# dm646x_cslr_sys_001 register map
Vendor: Texas Instruments
Peripheral module from a debugger description file.
Registers are 32-bit, access not given, reset 0x0 unless marked. A register's access mark holds for its fields unless they carry their own. Offsets are as the file gives them; lines under a group give offsets from that group; [hi:lo] are bit positions; {n}, {i} and the like mark numbered series; 'fields as' and 'values as' point back to an identical list; <NAME> marks a mode.

## SYS — System Module (ch5_Chip_Configuration_0p19.pdf)
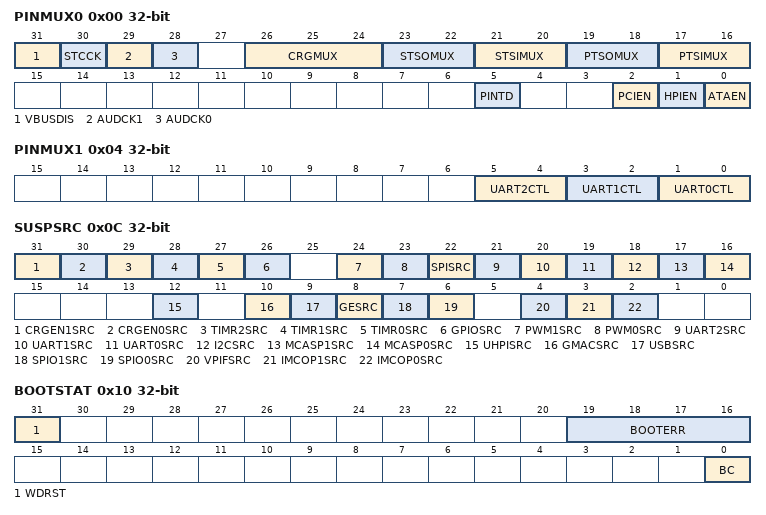
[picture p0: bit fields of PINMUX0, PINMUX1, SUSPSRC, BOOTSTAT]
0x00 PINMUX0
  [31] VBUSDIS rw — Disable USB_DRVVBUS output 0 = USB_DRVVBUS function selected 1 = GP22 function selected
    0=USB_DRVVBUS; 1=GP22
  [30] STCCK rw — Enable STC source clock input 0 = GP04_INT04 function selected 1 = STCSRC_CLKIN function selected
    0=GP04_INT04; 1=STCSRC_CLKIN
  [29] AUDCK1 rw — Enable AUDIO_CLK1 output 0 = GP02_INT02 function selected 1 = AUDIO_CLK1 function selected
    0=GP02_INT02; 1=ENABLE
  [28] AUDCK0 rw — Enable AUDIO_CLK0 output 0 = GP03_INT03 function selected 1 = AUDIO_CLK0 function selected
    0=GP03_INT03; 1=ENABLE
  [26:24] CRGMUX rw — CRGEN pin mux control (See Section 5.2.9) 000 = No CRGEN signals enabled 001 = CRGEN1 selection enabled (mux'd with UART2 data) 010 = Reserved (no CRGEN signals enabled) 011 = Reserved (no CRGEN signals enabled) 100 = CRGEN0 selection enabled (mux'd with UART2_CTS & PWM0) 101 = CRGEN0 & CRGEN1 selection enabled 110 = CRGEN0 selection enabled (mux'd with UART2 data) 111 = Reserved (no CRGEN signals enabled)
    0=NOCRGEN; 1=CRGEN1_MUXWITH_UART2DATA; 4=CRGEN0_MUXWITH_PWM0; 5=CRGEN0_CRGEN1; 6=CRGEN0_MUXWITH_UART2DATA
  [23:22] STSOMUX rw — STSO pin mux control (See Section 5.2.8) 0x = No STSO signals enabled 10 = STSO selection enabled (mux'd on VPIF_DOUT pins) 11 = STSO selection enabled (mux'd on UART0_RIN, UART2_CTSn, PWM0, and PWM1 pins)
    0=NOSTSO; 2=ENABLE_MUXWITH_VPIF_DOUT; 3=ENABLE_MUXWITH_UART_PWM
  [21:20] STSIMUX rw — STSI pin mux control (See Section 5.2.7) 00 = No STSI signals enabled 01 = STSI selection enabled (mux'd on UART0 pins) 10 = STSI selection enabled (mux'd on VPIF_DOUT pins) 11 = STSI selection enabled (mux'd on VPIF_DIN pins)
    0=NOSTSI; 1=ENABLE_MUXWITH_UART0; 2=ENABLE_MUXWITH_VPIF_DOUT; 3=ENABLE_MUXWITH_VPIF_DIN
  [19:18] PTSOMUX rw — PTSO pin mux control 00 = No PTSO signals enabled 01 = No PTSO signals enabled 10 = PTSO parallel muxing enabled (mux w/ VPIF_DIN) 11 = PTSO serial muxing enabled (mux D w/ UART1)
    0=NOPTSO; 1=NOPTSO1; 2=ENABLE_MUX_VPIF_DIN; 3=ENABLE_MUX_UART1
  [17:16] PTSIMUX rw — PTSO pin mux control 00 = No PTSI signals enabled 01 = No PTSI signals enabled 10 = PTSI parallel muxing enabled (mux w/ VPIF_DIN) 11 = PTSI serial muxing enabled (mux D w/ UART1)
    0=NOPTSI; 1=NOPTSI1; 2=ENABLE_MUX_VPIF_DIN; 3=ENABLE_MUX_UART1
  [5] PINTD rw — PCI INTD Function 0 = Pin functions as GP05_INT05 1 = Pin functions as PCI INTD input
    0=GP05_INT05_FUN; 1=PCI_INTD_FUN
  [2] PCIEN rw — PCI Function Enable
  [1] HPIEN rw — UHPI Function Enable
  [0] ATAEN rw — ATA Function Enable
0x04 PINMUX1
  [5:4] UART2CTL rw — UART2 pin configuration 00 = UART function with flow control 01 = UART function without flow control 10 = IrDA/CIR function 11 = GPIO function (Individual pin functions may be overridden by PTSIMUX, CRGEN0 and CRGEN1 values)
    0=UART_WITH_FLOW; 1=UART_WITHOUT_FLOW; 2=IRDA_CIR; 3=GPIO
  [3:2] UART1CTL rw — UART1 pin configuration 00 = UART function with flow control 01 = UART function without flow control 10 = IrDA/CIR function 11 = GPIO function (Individual pin functions may be overridden by PTSIMUX and PTSOMUX values)
    0=UART_WITH_FLOW; 1=UART_WITHOUT_FLOW; 2=IRDA_CIR; 3=GPIO
  [1:0] UART0CTL rw — UART0 pin configuration (See Section 5.2.10) 00 = UART function with modem control 01 = UART function without modem control 1x = IrDA/CIR function (Individual pin functions may be overridden by PTSOMUX, value)
    0=UART_WITH_MODEM; 1=UART_WITHOUT_MODEM; 2=IRDA_CIR
0x08 DSPBOOTADDR rw reset 0x42200000 — DSP Boot Address
  [31:0] BOOTADDR — \hDSP Boot Address . Upper 22 bits of DSP reset vector are stored in upper 22 bits of the register and the 10 LSBs are ignored . Note that this must point to an address range from which GEM can perform instruction fetches. Thus is limited to the following address ranges: L1P : 0x00E0:0000  0x00E0:7FFF. AEMIF: 0x42xx:xxxx  0x49FF:FFFF. DDR : 0x8000:0000  0x8FFF:FFFF
0x0C SUSPSRC — Determines which processor emulator (ARM or GEM) controls peripheral emulation suspend
  [31] CRGEN1SRC rw — Clock Recovery Generator 1 emulation
    0=ARMEMU (Receives EMU suspend on ARM suspend); 1=GEMEMU (Receives EMU suspend on GEM suspend)
  [30] CRGEN0SRC rw — Clock Recovery Generator 0 emulation
    0=ARMEMU; 1=GEMEMU
  [29] TIMR2SRC rw — EMU suspend source for TIMER2 (WDTIMER)
    values as CRGEN1SRC
  [28] TIMR1SRC rw — EMU suspend source for TIMER1
    values as CRGEN1SRC
  [27] TIMR0SRC rw — EMU suspend source for TIMER0
    values as CRGEN1SRC
  [26] GPIOSRC rw — EMU suspend source for GPIO
    values as CRGEN1SRC
  [24] PWM1SRC rw — EMU suspend source for PWM1
    values as CRGEN1SRC
  [23] PWM0SRC rw — EMU suspend source for PWM0
    values as CRGEN1SRC
  [22] SPISRC rw — EMU suspend source for SPI
    values as CRGEN1SRC
  [21] UART2SRC rw — EMU suspend source for UART2
    values as CRGEN1SRC
  [20] UART1SRC rw — EMU suspend source for UART1
    values as CRGEN1SRC
  [19] UART0SRC rw — EMU suspend source for UART0
    values as CRGEN1SRC
  [18] I2CSRC rw — EMU suspend source for I2C
    values as CRGEN1SRC
  [17] MCASP1SRC rw — EMU suspend source for MCASP1
    values as CRGEN1SRC
  [16] MCASP0SRC rw — EMU suspend source for MCASP0
    values as CRGEN1SRC
  [12] UHPISRC rw — EMU suspend source for UHPI
    values as CRGEN1SRC
  [10] GMACSRC rw — Ethernet MAC emulation suspend source
    values as CRGEN1SRC
  [9] USBSRC rw — EMU suspend source for USB
    values as CRGEN1SRC
  [8] GESRC rw — Graphic Engine emulation suspend source
    values as CRGEN1SRC
  [7] SPIO1SRC rw — Stream I/O 1 emulation suspend source
    values as CRGEN1SRC
  [6] SPIO0SRC rw — Stream I/O 0 emulation suspend source
    values as CRGEN1SRC
  [4] VPIFSRC rw — Video Port emulation suspend source
    values as CRGEN1SRC
  [3] IMCOP1SRC rw — HD-ImCOP1 emulation suspend source
    values as CRGEN1SRC
  [2] IMCOP0SRC rw — HD-ImCOP0 emulation suspend source
    values as CRGEN1SRC
0x10 BOOTSTAT — Boot Status
  [31] WDRST rw — Watchdog Timer Reset 0 = Device reset was not a result of timeout. 1 = Device was reset be a watchdog timer timeout. This is a "sticky" bit that can be used to debug WD timeout conditions. The bit is set when a WD timeout occurs (TOUT4). This bit is reset (to 0) by a PORn reset only. It is NOT cleared by a Warm Reset or soft reset. The bit may be cleared by writing a '1'.
    0=NOTIMEOUT; 1=TIMEOUT
  [19:16] BOOTERR rw — Boot Error 0000 = No Boot Error Others = Bootloader detected boot error The exact meaning of the various error codes will be determined by the bootloader software.
    0=NOERROR
  [0] BC rw — Boot Complete 0 = Host has not complete its boot sequence 1 = Host boot sequence is complete This bit may be optionally set by a host boot device (such as PCI or UHPI) to indicate that it has finished loading code. The ARM926 can poll this bit to determine whether to continue the boot process.
    0=BOOT_NOTCOMPLETE; 1=BOOT_COMPLETE
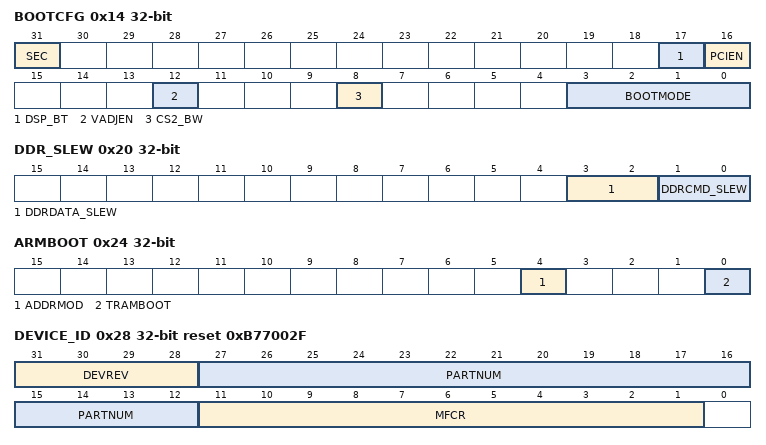
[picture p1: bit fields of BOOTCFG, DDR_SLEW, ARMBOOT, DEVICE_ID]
0x14 BOOTCFG
  [31] SEC ro — Secure Device 0 = Non-secure device 1 = Secure device This bit is not latched at the end of global hard reset.
    0=NON_SECURE_DEV; 1=SECURE_DEV
  [17] DSP_BT ro — DSP Boot 0 = ARM boots GEM 1 = GEM self-boots This bit has no meaning on GEM-only devices. For ARM/GEM devices, will cause the GEM to be released from reset automatically. GEM will boot from secure ROM on secure devices or from AEMIF on nonsecure devices. If BOOTMODE = 0001 or 0010, or PCIEN=1 on non-secure devices, then GEM self-boot will fail since the AEMIF will be disabled.
    0=ARM_BOOT; 1=GEM_SELF_BOOT
  [16] PCIEN ro — PCI Enable 0 = PCI Disabled 1 = PCI Enabled Disables internal pullup and pulldown resistors on PCI pins and configures pin muxing for PCI.
    0=DISABLE; 1=ENABLE
  [12] VADJEN ro — Voltage Adjust Enable 0 = SmartReflex outputs disabled 1 = SmartReflex outputs enabled Determines whether GP_INT[07:06] will function as GPIOs or SmartReflex control outputs.
    0=DISABLE; 1=ENABLE
  [8] CS2_BW ro — AEMIF CS2 Default Bus Width 0 = Default to 8-bit operation 1 = Default to 16-bit operation Determines the default bus width of the AEMIF CS2 memory space. This ensures that boot from AEMIF (ARM or GEM) will correctly read the attached memory.
    0=8BIT; 1=16BIT
  [3:0] BOOTMODE ro — Boot Mode 0000 = EMU Boot 0001 = Reserved 0010 = UHPI-16 (if PCIEN = 0) PCI w/o auto-init (if PCIEN = 1) 0011 = UHPI-32 (if PCIEN = 0) PCI w/ auto-init (if PCIEN = 1) 0100 = AEMIF direct (if SEC = 0), AEMIF through ROM (if SEC = 1) Error (if PCIEN = 1)  default to UART0 0101 = Reserved 0110 = I2C Boot 0111 = NAND Flash (if PCIEN = 0) Error (if PCIEN = 1) 1000 = UART0 Boot 1001 = Emulation Boot 1010 = VLYNQ Boot 1011 = EMAC Boot 1110 = SPI Boot Others = Reserved
0x18 SMTREFLEX — Smart Reflex control status Register
  [1:0] SMTREFLEX ro — eFuse programmed adjustment values for 1.2V core operation. Reflects the value output on the SMTREFLEX[1:0] pins.
0x20 DDR_SLEW — DDR Slew Rate
  [3:2] DDRDATA_SLEW ro — DDR data
  [1:0] DDRCMD_SLEW ro — DDR command
0x24 ARMBOOT — ARM926 Boot Control
  [4] ADDRMOD rw — IAHB Address Modification 0 = No address modification 1 = Address bit 30 is tied high to modify IAHB fetch address to point to AEMIF
    0=DISABLE_MODIFY; 1=ENABLE_MODIFY
  [0] TRAMBOOT rw — ARM TCM RAM Boot 0 = Use BTMODE selected bootmode 1 = Boot from ITCM RAM
    0=USE_BTMODE; 1=RAM_BOOT
0x28 DEVICE_ID reset 0xB77002F — Device Identification
  [31:28] DEVREV ro — Device revision
  [27:12] PARTNUM ro — Device part number (unique JTAG ID)
  [11:1] MFCR ro — Manufacturer's JTAG ID
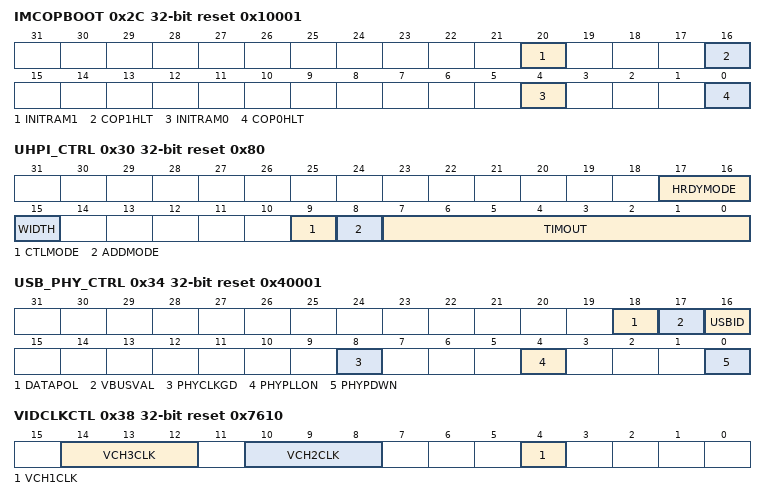
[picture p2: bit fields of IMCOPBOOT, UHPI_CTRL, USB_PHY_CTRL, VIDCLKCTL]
0x2C IMCOPBOOT reset 0x10001 — ImCOP Boot Control register
  [20] INITRAM1 rw — ImCOP1 INITRAM Input 0 = Internal TCM disabled 1 = Internal TCM enabled This bit determines if ARM fetches its first instruction from TCM memory or external memory. The default value is 0 at reset. After TCM RAM is loaded, software may set the value to 1 to enable subsequent resets from TCM
    0=TCM_DISABLE; 1=TCM_ENABLE
  [16] COP1HLT rw — ImCOP1 Fetch Halt 0 = IAHB fetch enabled 1 = IAHB fetch stalled This bit determines the value on the WAIT input of the ARM968 AHB bus. By pulling WAIT high, the instruction fetch is stalled. This allows the TCM RAM to be loaded by another device or EDMA. Afterwards, the ImCOP can be reset again with INITRAM enabled and COP1HLT disabled to execute from TCM
    0=IAHB_FETCH_ENABLE; 1=IAHB_FETCH_STALLED
  [4] INITRAM0 rw — ImCOP0 INITRAM Input 0 = Internal TCM disabled 1 = Internal TCM enabled This bit determines if ARM fetches its first instruction from TCM memory or external memory. The default value is 0 at reset. After TCM RAM is loaded, software may set the value to 1 to enable subsequent resets from TCM
    0=TCM_DISABLE; 1=TCM_ENABLE
  [0] COP0HLT rw — ImCOP0 Fetch Halt 0 = IAHB fetch enabled 1 = IAHB fetch stalled This bit determines the value on the WAIT input of the ARM968 AHB bus. By pulling WAIT high, the instruction fetch is stalled. This allows the TCM RAM to be loaded by another device or EDMA. Afterwards, the ImCOP can be reset again with INITRAM enabled and COP1HLT disabled to execute from TCM
    0=IAHB_FETCH_ENABLE; 1=IAHB_FETCH_STALLED
0x30 UHPI_CTRL reset 0x80 — UHPI Control
  [17:16] HRDYMODE rw — HRDY output mode 00 = HRDYn (active low) signal is output 01 = HRDY (active high) signal is output 10 = InternalHRDYn signal is output 11 = InternalHRDY signal is output
    0=HRDYN_ACTIVE_LOW; 1=HRDY_ACTIVE_HIGH; 2=INTERNAL_HRDYN; 3=INTERNAL_HRDY
  [15] WIDTH rw — UHPI Data Width 0 = Half width (16-bit) data bus 1 = Full width (32-bit) data bus This bit value must be determined before releasing the UHPI from reset to ensure correct UHPI operation.
    0=16BIT; 1=32BIT
  [9] CTLMODE rw — HPIC register write access 0 = Host 1 = DaVinci-HD (if ADDMODE = 1)
    0=HOST; 1=DAVINCIHD
  [8] ADDMODE rw — HPIA register write access 0 = Host 1 = DaVinci-HD
    0=HOST; 1=DAVINCIHD
  [7:0] TIMOUT rw — Host burst write timeout value
0x34 USB_PHY_CTRL reset 0x40001 — USB PHY Control
  [18] DATAPOL rw — Determines UDB data polarity 0 = Inverted data 1 = Normal data polarity
    0=INVERTED; 1=NORMAL
  [17] VBUSVAL rw — VBUS sense control 0 = Disabled 1 = Session start
    0=DISABLE; 1=SESSION_START
  [16] USBID rw — USB Mode 0 = Host 1 = Peripheral
    0=HOST; 1=PERIPHERAL
  [8] PHYCLKGD ro — USB PHY Power and Clock Good 0 = Phy power not ramped or PLL not locked 1 = Phy power is good and PLL is locked
    0=NOT_GOOD; 1=GOOD
  [4] PHYPLLON rw — USB PHY PLL suspend override 0 = Normal PLL operation 1 = Override PLL suspend state
    0=NORMAL_OPER; 1=OVERRIDE_SUSP_STATE
  [0] PHYPDWN rw — USB PHY power down control 0 = PHY powered 1 = PHY power off
    0=PWRED; 1=PWROFF
0x38 VIDCLKCTL reset 0x7610 — Video Clock Control
  [14:12] VCH3CLK rw — Video Channel 3 Clock Source Selects the clock source for the Ch3 output source clock. 000 : CRG0_VCXI (external pin) 001 : CRG1_VCXI (external pin) 010 : Sysclk8 (PLLCTRL0) 011 : Auxclk (PLLCTRL0) 100 : VPIF_CLKIN0 (external pin) 101 : V27_PLLIN (external pin) 110 : VPIF_CLKIN2 (external pin) 111 : VPIF_CLKIN3 (external pin)
    0=CRG0_VCXI; 1=CRG1_VCXI; 2=Sysclk8; 3=Auxclk; 4=VPIF_CLKIN0; 5=V27_PLLIN; 6=VPIF_CLKIN2; 7=VPIF_CLKIN3
  [10:8] VCH2CLK rw — Video Channel 2 Clock Source Selects the clock source for the Ch2 output source clock. 000 : CRG0_VCXI (external pin) 001 : CRG1_VCXI (external pin) 010 : Sysclk8 (PLLCTRL0) 011 : Auxclk (PLLCTRL0) 100 : VPIF_CLKIN0 (external pin) 101 : V27_PLLIN (external pin) 110 : VPIF_CLKIN2 (external pin) 111 : Reserved
    0=CRG0_VCXI; 1=CRG1_VCXI; 2=Sysclk8; 3=Auxclk; 4=VPIF_CLKIN0; 5=V27_PLLIN; 6=VPIF_CLKIN2
  [4] VCH1CLK rw — Video Channel 1 Clock Source Selects the clock source for the Ch1 input clock. 0 : VPIF_CLKIN0 (external pin) 1 : VPIF_CLKIN1 (external pin)
    0=VPIF_CLKIN0; 1=VPIF_CLKIN1
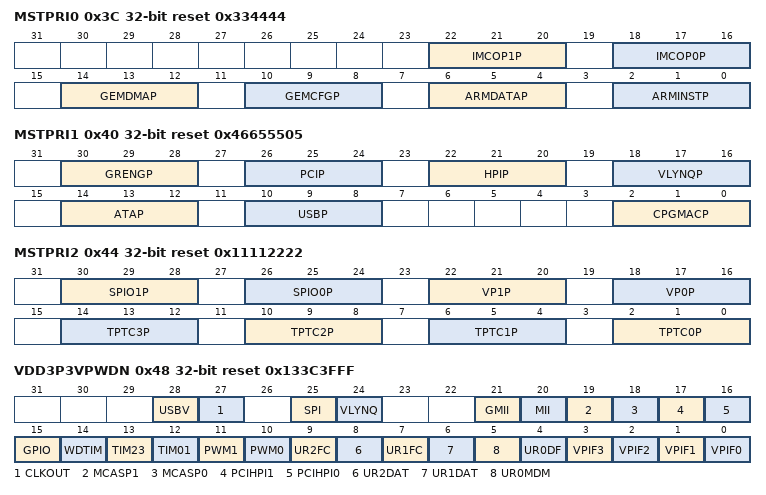
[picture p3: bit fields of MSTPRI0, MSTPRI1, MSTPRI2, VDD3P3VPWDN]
0x3C MSTPRI0 reset 0x334444 — Master Priorities Reg0
  [22:20] IMCOP1P rw — ImCOP1 bus priority
  [18:16] IMCOP0P rw — ImCOP0 bus priority
  [14:12] GEMDMAP rw — GEM DMA bus priority
  [10:8] GEMCFGP rw — GEM CFG bus priority
  [6:4] ARMDATAP rw — ARM DATA bus priority
  [2:0] ARMINSTP rw — ARM INSTRUCTION bus priority
0x40 MSTPRI1 reset 0x46655505 — Master Priorities Reg1
  [30:28] GRENGP rw — UHPI bus priority
  [26:24] PCIP rw — PCI bus priority
  [22:20] HPIP rw — HPI bus priority
  [18:16] VLYNQP rw — VLYNQ bus priority
  [14:12] ATAP rw — ATA bus priority
  [10:8] USBP rw — USB bus priority
  [2:0] CPGMACP rw — EMAC bus priority
0x44 MSTPRI2 reset 0x11112222 — Master Priorities Reg2
  [30:28] SPIO1P rw — SPIO1 bus priority
  [26:24] SPIO0P rw — SPIO0 bus priority
  [22:20] VP1P rw — Video Port1 bus priority
  [18:16] VP0P rw — Video Port0 bus priority
  [4n+2:4n] TPTC{n}P rw (n=0..3) — TPTC {n} bus priority
0x48 VDD3P3VPWDN reset 0x133C3FFF — VDD 3.3V I/O powerdown control
  [all] fields
    0=PWUP; 1=PWDOWN
  [28] USBV rw — USB_DRVBUS Powerdown Control: 0 = i/o cells powered up 1 = i/o cells powered down Controls USB_DRVVBUS pin.
  [27] CLKOUT rw — CLKOUT Powerdown Control: 0 = i/o cells powered up 1 = i/o cells powered down Controls CLKOUT pin. Defaults to powered to facilitate debug.
  [25] SPI rw — SPI Powerdown Control Controls 6 SPI interface pins
  [24] VLYNQ rw — VLYNQ Powerdown Control Controls 10 VLYNQ interface pins
  [21] GMII rw — GMIII Powerdown Control Controls the 10 pins used by GMII (Gigibit) only. MII_RFTCLK, MII_GMTCLK, MII_MTXD[7:4] and MII_MRXD[7:4]
  [20] MII rw — MIII Powerdown Control Controls the 17 pins used by (G)MII (10/100/Gig) and MDIO interfaces. MII_MTCLK, MII_MTXD[3:0], MII_MTXEN, MII_MCOL, MII_MCRS, MII_MRCLK, MII_MRXD[3:0], MII_MRXDV, MII_MRXER, MDIO_MDCLK, and MDIO_MDIO
  [19] MCASP1 rw — McASP1 Powerdown Control Controls the 3 McASP1 pins
  [18] MCASP0 rw — McASP0 Powerdown Control Controls the 12 McASP1 pins
  [17] PCIHPI1 rw — PCI / UHPI / AEMIF / ATA Powerdown Control Controls the 27 pins used by ATA or PCI, UHPI, or AEMIF. Defaults to powered up for NOR boot
  [16] PCIHPI0 rw — PCI / UHPI / AEMIF Powerdown Control Controls the 29 pins used by PCI, UHPI, or AEMIF but not shared with ATA. Does not include GP[7:5]_INT[7:5] Defaults to powered up for NOR boot
  [15] GPIO rw — GPIO Powerdown Control Controls the 8 GP_INT[7:0] pins. Defaults to powered up.
  [14] WDTIM rw — WD Timer Powerdown Control Controls the WD Timer pin TOUT4.
  [13] TIM23 rw — Timer1 Powerdown Control Controls the 3 Timer1 pins TIN2, TOUT2, TOUT3
  [12] TIM01 rw — Timer0 Powerdown Control Controls the 4 Timer0 pins TIN0, TOUT0. TIN1, TOUT1
  [11] PWM1 rw — PWM1 Powerdown Control Controls the PWM1 / GP36 pin
  [10] PWM0 rw — PWM0 Powerdown Control Controls the PWM0 / GP37 / CRG0_PWMO pin
  [9] UR2FC rw — UART2 Flow Control Powerdown Control Controls the UART2_RTSn / PTSI_PSTART and UART2_CTSn / CRG0_PWMO pins
  [8] UR2DAT rw — UART2 Data Powerdown Control Controls the UART2_RXD / CRG1_VCXI and UART2_TXD / CRG1_PWMO pins
  [7] UR1FC rw — UART1 Flow Control Powerdown Control Controls the UART1_RTSn / PTSI_ERR and UART1_CTSn / PTSI_VALID pins
  [6] UR1DAT rw — UART1 Data Powerdown Control Controls the UART1_RXD / PTSI_D7 and UART1_TXD / PTSO_D7 pins
  [5] UR0MDM rw — UART0 Modem Control Powerdown Control Controls UART0_DTRn / PTSO_VALID, UART0_DSRn / PTSO_PSTART, UART0_DCDn / PTSO_ERR and UART0_RIN / GP08 pins
  [4] UR0DF rw — UART0 Data and Flow Powerdown Control Controls UART0_RXD, UART0_TXD, UART0_RTSn, and UART0_CTSn pins
  [3] VPIF3 rw — VPIF MSB Output Powerdown Control Controls the VPIF_DOUT[15:8] / STSO / STSI, VPIF_CLKIN3 / STSO_CLK, and VPIF_CLKO3 / PTSO_CLK pins
  [2] VPIF2 rw — VPIF LSB Output Powerdown Control Controls the VPIF_DOUT[7:0], VPIF_CLKIN2, and VPIF_CLKO2 pins
  [1] VPIF1 rw — VPIF MSB Input Powerdown Control Controls the VPIF_DIN[15:8] / PTSI_D[7:0], and VPIF_CLKIN1 pins
  [0] VPIF0 rw — VPIF LSB Input Powerdown Control Controls the VPIF_DIN[7:0] / PTSO_D[7:0] / STSI and VPIF_CLKIN0 pins
0x4C DFTENABLE — Enable access to DFT MMRs
  [0] DFT_EN rw — Setting the DFTEN bit allows program access to the DFT MMR registers (including the die ID register).
    0=DISABLE; 1=ENABLE
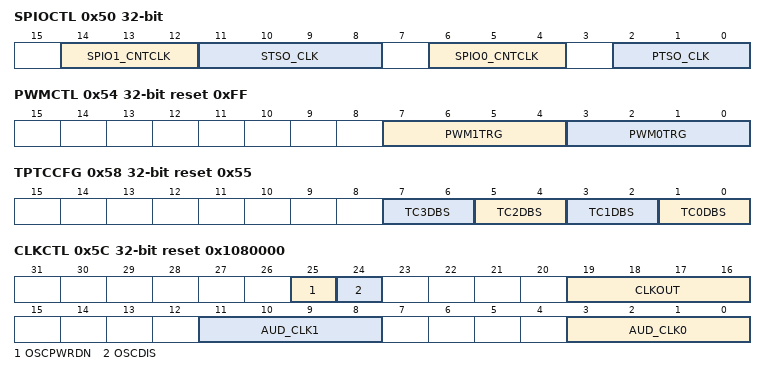
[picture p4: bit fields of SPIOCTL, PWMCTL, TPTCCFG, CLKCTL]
0x50 SPIOCTL — SPIO Control Register
  [14:12] SPIO1_CNTCLK rw — SPIO1 Counter Clock Source Selects the clock source for Stream I/O 1 module's counter (m27_clk signal) 000 : CRG1_VCXI (external pin) 001 : STCSRC_CLKIN (external pin) 010 : AUXCLK (PLLCTL0 output  27 MHz) 011 : CRG0_VCXI (external pin) 100 : VPIF_CLKIN2 (external pin) 101 : VPIF_CLKIN3 (external pin) 110 : Reserved 111 : Reserved
    0=CRG1_VCXI; 1=STCSRC_CLKIN; 2=AUXCLK; 3=CRG0_VCXI; 4=VPIF_CLKIN2; 5=VPIF_CLKIN3
  [11:8] STSO_CLK rw — SPIO1 STSO Output Clock Source Selects the clock source for Stream I/O 1 output source clock (str_tx_clk_i signal) 0000 : CRG1_VCXI (external pin) 0001 : STCSRC_CLKIN (external pin) 0010 : Sysclk6 (PLLCTL0) 0011 : Sysclkbp PLLCTL0) 0100 : VPIF_CLKIN0 (external pin) 0101 : STSI_CLK (external pin) 0110 : VPIF_CLKIN2 (external pin) 0111 : Reserved 1000 : CRG0_VCXI 1001 : Reserved 1xx1 : Reserved
    0=CRG1_VCXI; 1=STCSRC_CLKIN; 2=Sysclk6; 3=Sysclkbp; 4=VPIF_CLKIN0; 5=STSI_CLK; 6=VPIF_CLKIN2; 8=CRG0_VCXI
  [6:4] SPIO0_CNTCLK rw — SPIO0 Counter Clock Source Selects the clock source for Stream I/O 0 module's counter (m27_clk signal) 000 : CRG0_VCXI (external pin) 001 : STCSRC_CLKIN (external pin) 010 : AUXCLK (PLLCTL0 output  27 MHz) 011 : CRG1_VCXI (external pin) 100 : VPIF_CLKIN0 (external pin) 101 : VPIF_CLKIN1 (external pin) 110 : Reserved 111 : Reserved
    0=CRG0_VCXI; 1=STCSRC_CLKIN; 2=AUXCLK; 3=CRG1_VCXI; 4=VPIF_CLKIN0; 5=VPIF_CLKIN1
  [2:0] PTSO_CLK rw — SPIO0 PTSO Output Clock Source Selects the clock source for Stream I/O 0 output source clock (str_tx_clk_i signal) 000 : CRG0_VCXI (external pin) 001 : STCSRC_CLKIN (external pin) 010 : Sysclk5 (PLLCTL0) 011 : Sysclkbp PLLCTL0) 100 : VPIF_CLKIN0 (external pin) 101 : VPIF_CLKIN1 (external pin) 110 : PTSI_CLK (external pin) 111 : CRG1_VCXI (external pin)
    0=CRG0_VCXI; 1=STCSRC_CLKIN; 2=Sysclk5; 3=Sysclkbp; 4=VPIF_CLKIN0; 5=VPIF_CLKIN1; 6=PTSI_CLK; 7=CRG1_VCXI
0x54 PWMCTL reset 0xFF — PWM Control Register
  [7:4] PWM1TRG rw — PWM1 Trigger Source 0000 = GPIO0 1000 = VPIF Vert Int0 0001 = GPIO1 1001 = VPIF Vert Int1 0010 = GPIO2 1010 = VPIF Vert Int2 0011 = GPIO3 1011 = VPIF Vert Int3 0100 = GPIO4 1100 = Disabled 0101 = GPIO5 1101 = Disabled 0110 = GPIO6 1110 = Disabled 0111 = GPIO7 1111 = Disabled
  [3:0] PWM0TRG rw — PWM0 Trigger Source 0000 = GPIO0 1000 = VPIF Vert Int0 0001 = GPIO1 1001 = VPIF Vert Int1 0010 = GPIO2 1010 = VPIF Vert Int2 0011 = GPIO3 1011 = VPIF Vert Int3 0100 = GPIO4 1100 = Disabled 0101 = GPIO5 1101 = Disabled 0110 = GPIO6 1110 = Disabled 0111 = GPIO7 1111 = Disabled
0x58 TPTCCFG reset 0x55 — TPTC Configuration
  [all] fields
    0=16BYTE; 1=32BYTE; 2=64BYTE
  [2n+1:2n] TC{n}DBS rw (n=0..3) — TC{n} Default Burst Size 00 = 16 byte 01 = 32 byte 10 = 64 byte 11 = reserved
0x5C CLKCTL reset 0x1080000 — Oscillator and output control
  [25] OSCPWRDN rw — Aux Oscillator Powerdown Controls internal bias resistor connection 0 = Internal bias resistor connected (normal operation) 1 = Internal bias resistor disconnected (external bias resistor required or clock input used)
    0=BIAS_REG_CONNECTED; 1=BIAS_REG_DISCONNECTED
  [24] OSCDIS rw — Aux Oscillator Disable Disables the oscillator 0 = Oscillator enabled (normal operation) 1 = Oscillator disabled (clock input used or not Aux clock required)
    0=AUX_OSC_ENABLE; 1=AUX_OSC_DISABLE
  [19:16] CLKOUT rw — CLKOUT Source Selects the clock source for the CLKOUT output 0000 : Disabled 1000 : Sysclk8 0001 : Auxclk 1001 : Sysclk9 0010 : Obsclk 1010 : X1_AUX 0011 : Sysclk3 1011 : Reserved 0100 : Sysclk4 1100 : Reserved 0101 : Sysclk5 1101 : Reserved 0110 : Sysclk6 1110 : Reserved 0111 : Sysclk7 1111 : Reserved
  [11:8] AUD_CLK1 rw — AUDIO_CLK1 Source Selects the clock source for the AUDIO_CLK1 output 0000 : Disabled 1000 : X1_AUX 0001 : Auxclk 1001 : V27_PLLIN 0010 : CRG0_VCXI 1010 : Reserved 0011 : CRG1_VCXI 1011 : Reserved 0100 : VPIF_CLKIN0 1100 : Reserved 0101 : VPIF_CLKIN1 1101 : Reserved 0110 : VPIF_CLKIN2 1110 : Reserved 0111 : VPIF_CLKIN3 1111 : Reserved
  [3:0] AUD_CLK0 rw — AUDIO_CLK0 Source Selects the clock source for the AUDIO_CLK0 output 0000 : Disabled 1000 : X1_AUX 0001 : Auxclk 1001 : V27_PLLIN 0010 : CRG0_VCXI 1010 : Reserved 0011 : CRG1_VCXI 1011 : Reserved 0100 : VPIF_CLKIN0 1100 : Reserved 0101 : VPIF_CLKIN1 1101 : Reserved 0110 : VPIF_CLKIN2 1110 : Reserved 0111 : VPIF_CLKIN3 1111 : Reserved
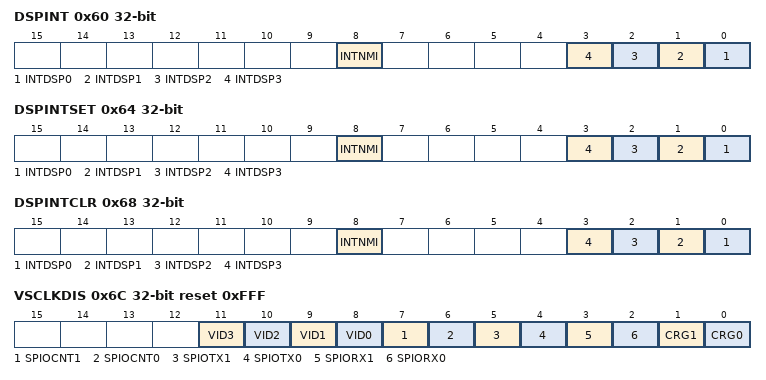
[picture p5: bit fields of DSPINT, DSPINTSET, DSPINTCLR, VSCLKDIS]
0x60 DSPINT — ARM to DSP Interrupt Status
  [all] fields
    0=NOINT; 1=ACTIVEINT
  [8] INTNMI ro — DSP NMI Status
  [n] INTDSP{n} ro (n=0..3) — ARM to DSP Int{n} Status
0x64 DSPINTSET — ARM to DSP Interrupt Set
  [all] fields
    0=NOINT; 1=SETINT
  [8] INTNMI rw — DSP NMI Set
  [n] INTDSP{n} rw (n=0..3) — ARM to DSP Int{n} Set
0x68 DSPINTCLR — ARM to DSP Interrupt Clear
  [all] fields
    0=NOINT; 1=CLRINT
  [8] INTNMI rw — DSP NMI Clear
  [n] INTDSP{n} rw (n=0..3) — ARM to DSP Int{n} Clear
0x6C VSCLKDIS reset 0xFFF — Video and Stream I/O clock disable
  [all] fields
    0=ENABLE; 1=DISABLE
  [11] VID3 rw — VPIF Channel 3 Clock Disable 0 = clock enabled 1 = clock disabled
  [10] VID2 rw — VPIF Channel 2 Clock Disable: 0 = clock enabled 1 = clock disabled
  [9] VID1 rw — VPIF Channel 1 Clock Disable: 0 = clock enabled 1 = clock disabled
  [8] VID0 rw — VPIF Channel 0 Clock Enable: 0 = clock enabled 1 = clock disabled
  [7] SPIOCNT1 rw — Stream I/O 1 Counter Clock Disable
  [6] SPIOCNT0 rw — Stream I/O 0 Counter Clock Disable
  [5] SPIOTX1 rw — Stream I/O 1 Transmit Clock Disable
  [4] SPIOTX0 rw — Stream I/O 0 Transmit Clock Disable
  [3] SPIORX1 rw — Stream I/O 1 Receive Clock Disable
  [2] SPIORX0 rw — Stream I/O 0 Receive Clock Disable
  [1] CRG1 rw — CRGEN1 Clock Disable
  [0] CRG0 rw — CRGEN0 Clock Disable
0x70 ARMINT — DSP to ARM Interrupt Status
  [0] INTARM0 ro — DSP to ARM Int0 Status
    0=NOINT; 1=ACTIVEINT
0x74 ARMINTSET — DSP to ARM Interrupt Set
  [0] INTARM0 rw — DSP to ARM Int0 Set
    0=NOINT; 1=SETINT
0x78 ARMINTCLR — DSP to ARM Interrupt Clear
  [0] INTARM0 rw — DSP to ARM Int0 Clear
    0=NOINT; 1=CLRINT
0x7C ARMWAIT reset 0x1 — ARM memory wait state control
  [0] ARMWAIT rw — ARM TCM Ram wait state configuration 0 = TCM RAM wait state disabled 1 = TCM RAM wait state enabled
    0=DISABLE; 1=ENABLE
0x80 SEC_PSEUDO0 — Secure ROM pseudo register 0
  [31:0] Reserved — (access N)
0x84 SEC_PSEUDO1 — Secure ROM pseudo register 1
  [31:0] Reserved — (access N)
